# MB9BF36xx register map
File version: 1.0
CPU: 
Registers are 8-bit, read-write, reset 0x0 unless marked. A register's access mark holds for its fields unless they carry their own. Offsets are from the block's base; [hi:lo] are bit positions; {n}, {i} and the like mark numbered series.

## DAC0 — peripheral DAC0
Base 0x40033000
Same registers: DAC1 0x40033008
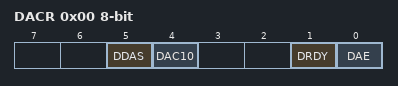
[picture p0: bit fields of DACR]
0x00 DACR
  [5] DDAS, [4] DAC10, [1] DRDY ro, [0] DAE
0x04 DADR 16-bit reset not defined
  [9:0] DA

## EXTI — peripheral EXTI
Base 0x40030000
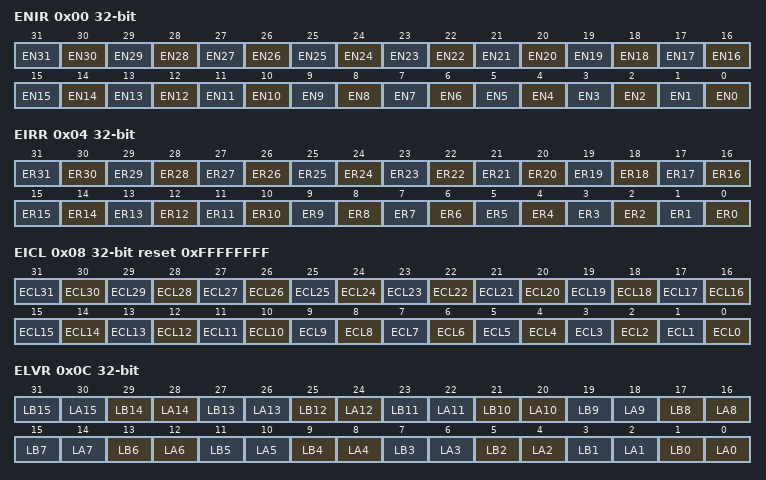
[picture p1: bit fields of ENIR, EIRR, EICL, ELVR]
0x00 ENIR 32-bit
  [n] EN{n} (n=0..31)
0x04 EIRR 32-bit ro reset not defined
  [n] ER{n} (n=0..31)
0x08 EICL 32-bit reset 0xFFFFFFFF
  [n] ECL{n} (n=0..31)
0x0C ELVR 32-bit
  [2n+1] LB{n} (n=0..15), [2n] LA{n} (n=0..15)
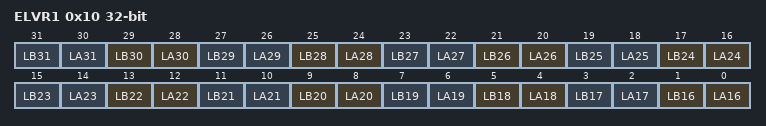
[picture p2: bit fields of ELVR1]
0x10 ELVR1 32-bit
  [2n-31] LB{n} (n=16..31), [2n-32] LA{n} (n=16..31)
0x14 NMIRR ro
  [0] NR
0x18 NMICL reset 0x1
  [0] NCL

## LVD — peripheral LVD
Base 0x40035000
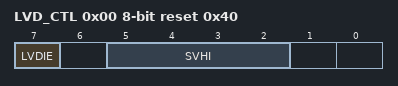
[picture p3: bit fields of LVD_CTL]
0x00 LVD_CTL reset 0x40
  [7] LVDIE, [5:2] SVHI
0x04 LVD_STR ro
  [7] LVDIR
0x08 LVD_CLR reset 0x80
  [7] LVDCL
0x0C LVD_RLR 32-bit reset 0x1
  [31:0] LVDLCK
0x10 LVD_STR2 ro reset 0x40
  [7] LVDIRDY

## DS — peripheral DS
Base 0x40035100
0x04 RCK_CTL reset 0x1
  [0] RTCCKE
0x700 PMD_CTL
  [0] RTCE
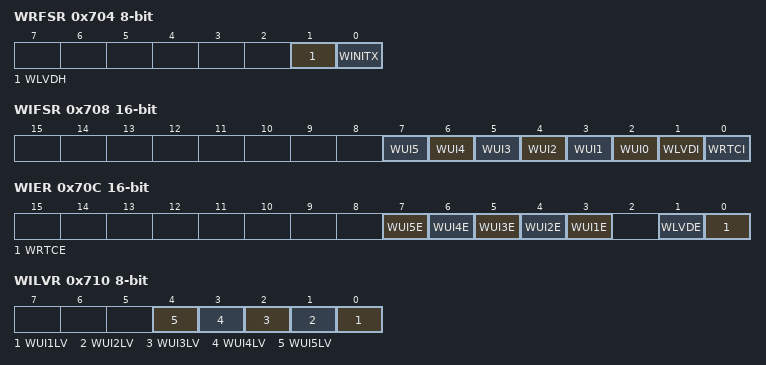
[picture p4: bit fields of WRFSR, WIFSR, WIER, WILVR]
0x704 WRFSR
  [1] WLVDH, [0] WINITX
0x708 WIFSR 16-bit ro
  [n+2] WUI{n} (n=0..5), [1] WLVDI, [0] WRTCI
0x70C WIER 16-bit
  [n+2] WUI{n}E (n=1..5), [1] WLVDE, [0] WRTCE
0x710 WILVR
  [n-1] WUI{n}LV (n=1..5)
0x714 DSRAMR
  [1:0] SRAMR
{0x7FF+i} BUR{i:02} (i=1..16)

## CRC — peripheral CRC
Base 0x40039000
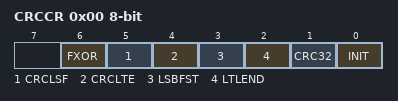
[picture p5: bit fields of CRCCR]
0x00 CRCCR
  [6] FXOR, [5] CRCLSF, [4] CRCLTE, [3] LSBFST, [2] LTLEND, [1] CRC32, [0] INIT
0x04 CRCINIT 32-bit reset 0xFFFFFFFF
  [31:0] D
0x08 CRCIN 32-bit
  [31:0] D
0x0C CRCR 32-bit ro reset 0xFFFFFFFF
  [31:0] D

## WC — peripheral WC
Base 0x4003A000
0x00 WCRD ro
  [5:0] CTR
0x01 WCRL
  [5:0] RLC
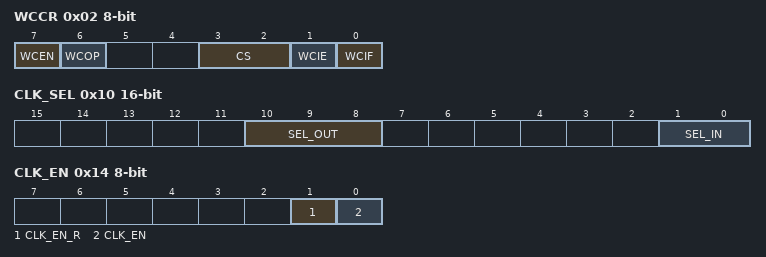
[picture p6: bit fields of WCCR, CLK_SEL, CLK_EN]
0x02 WCCR
  [7] WCEN, [6] WCOP ro, [3:2] CS, [1] WCIE, [0] WCIF
0x10 CLK_SEL 16-bit
  [10:8] SEL_OUT, [1:0] SEL_IN
0x14 CLK_EN
  [1] CLK_EN_R, [0] CLK_EN

## RTC — peripheral RTC
Base 0x4003B000
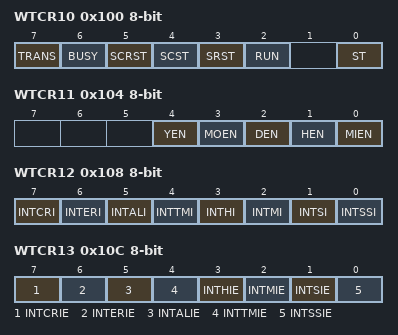
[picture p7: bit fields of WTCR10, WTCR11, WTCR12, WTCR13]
0x100 WTCR10
  [7] TRANS ro, [6] BUSY ro, [5] SCRST, [4] SCST, [3] SRST, [2] RUN ro, [0] ST
0x104 WTCR11
  [4] YEN, [3] MOEN, [2] DEN, [1] HEN, [0] MIEN
0x108 WTCR12
  [7] INTCRI, [6] INTERI, [5] INTALI, [4] INTTMI, [3] INTHI, [2] INTMI, [1] INTSI, [0] INTSSI
0x10C WTCR13
  [7] INTCRIE, [6] INTERIE, [5] INTALIE, [4] INTTMIE, [3] INTHIE, [2] INTMIE, [1] INTSIE, [0] INTSSIE
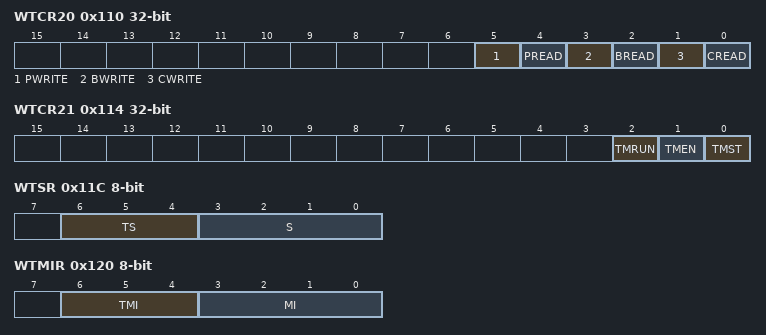
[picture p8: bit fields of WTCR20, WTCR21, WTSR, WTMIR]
0x110 WTCR20 32-bit
  [5] PWRITE, [4] PREAD, [3] BWRITE, [2] BREAD, [1] CWRITE, [0] CREAD
0x114 WTCR21 32-bit
  [2] TMRUN ro, [1] TMEN, [0] TMST
0x11C WTSR
  [6:4] TS, [3:0] S
0x120 WTMIR
  [6:4] TMI, [3:0] MI
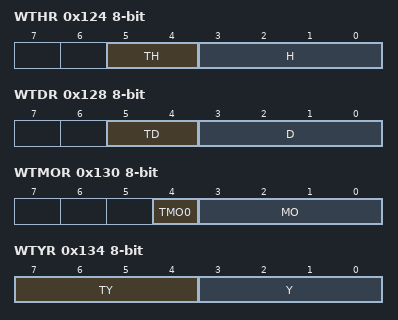
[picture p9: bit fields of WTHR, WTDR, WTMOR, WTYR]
0x124 WTHR
  [5:4] TH, [3:0] H
0x128 WTDR
  [5:4] TD, [3:0] D
0x12C WTDW
  [2:0] DW
0x130 WTMOR
  [4] TMO0, [3:0] MO
0x134 WTYR
  [7:4] TY, [3:0] Y
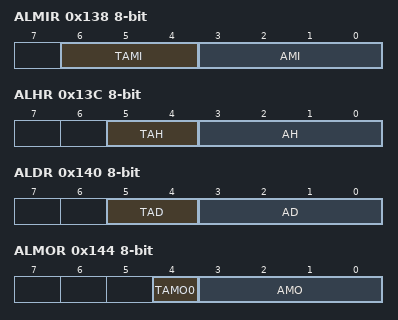
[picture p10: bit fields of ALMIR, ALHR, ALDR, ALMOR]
0x138 ALMIR
  [6:4] TAMI, [3:0] AMI
0x13C ALHR
  [5:4] TAH, [3:0] AH
0x140 ALDR
  [5:4] TAD, [3:0] AD
0x144 ALMOR
  [4] TAMO0, [3:0] AMO
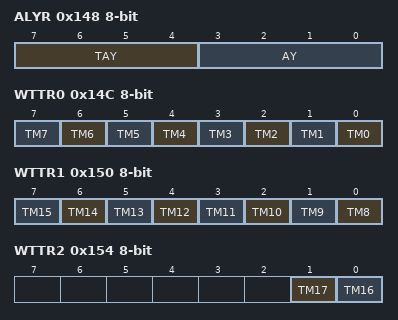
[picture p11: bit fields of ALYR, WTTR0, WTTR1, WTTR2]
0x148 ALYR
  [7:4] TAY, [3:0] AY
0x14C WTTR0
  [n] TM{n} (n=0..7)
0x150 WTTR1
  [n-8] TM{n} (n=8..15)
0x154 WTTR2
  [1] TM17, [0] TM16
0x158 WTCAL0
0x15C WTCAL1
  [1:0] WTCAL1
0x160 WTCALEN
  [0] WTCALEN
0x164 WTDIV
  [3:0] WTDIV
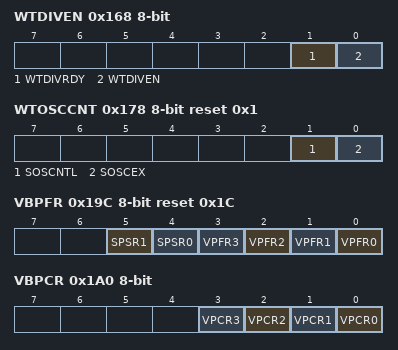
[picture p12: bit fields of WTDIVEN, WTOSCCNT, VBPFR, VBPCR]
0x168 WTDIVEN
  [1] WTDIVRDY ro, [0] WTDIVEN
0x16C WTCALPRD reset 0x13
  [5:0] WTCALPRD
0x170 WTCOSEL
  [0] WTCOSEL
0x174 VB_CLKDIV reset 0x7
  [7:0] DIV
0x178 WTOSCCNT reset 0x1
  [1] SOSCNTL, [0] SOSCEX
0x17C CCS reset 0x8
0x180 CCB reset 0x10
0x184 TRIM
0x188 BOOST reset 0x3
  [1:0] BOOST
0x18C EWKUP
  [0] WUP0
0x190 VDET reset 0x80
  [7] PON
0x194 FDET (reset mask 0x80)
0x198 HIBRST
  [0] HIBRST
0x19C VBPFR reset 0x1C
  [5] SPSR1, [4] SPSR0, [n] VPFR{n} (n=0..3)
0x1A0 VBPCR
  [n] VPCR{n} (n=0..3)
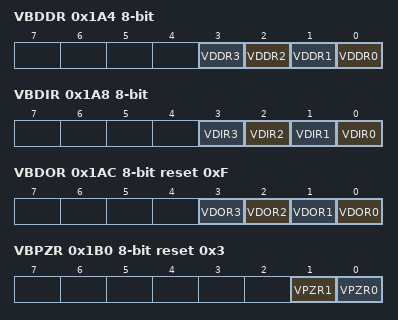
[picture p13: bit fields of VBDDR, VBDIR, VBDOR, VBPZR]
0x1A4 VBDDR
  [n] VDDR{n} (n=0..3)
0x1A8 VBDIR
  [n] VDIR{n} (n=0..3)
0x1AC VBDOR reset 0xF
  [n] VDOR{n} (n=0..3)
0x1B0 VBPZR reset 0x3
  [1] VPZR1, [0] VPZR0
{0x200+i} BREG{i:02} (i=0..9)
{0x20A+0x10*i} BREG{i}A (i=0..7)
{0x20B+0x10*i} BREG{i}B (i=0..7)
{0x20C+0x10*i} BREG{i}C (i=0..7)
{0x20D+0x10*i} BREG{i}D (i=0..7)
{0x20E+0x10*i} BREG{i}E (i=0..7)
{0x20F+0x10*i} BREG{i}F (i=0..7)
{0x206+i} BREG{i} (i=10..19)
{0x20C+i} BREG{i} (i=20..29)
{0x212+i} BREG{i} (i=30..39)
{0x218+i} BREG{i} (i=40..49)
{0x21E+i} BREG{i} (i=50..59)
{0x224+i} BREG{i} (i=60..69)
{0x22A+i} BREG{i} (i=70..79)
